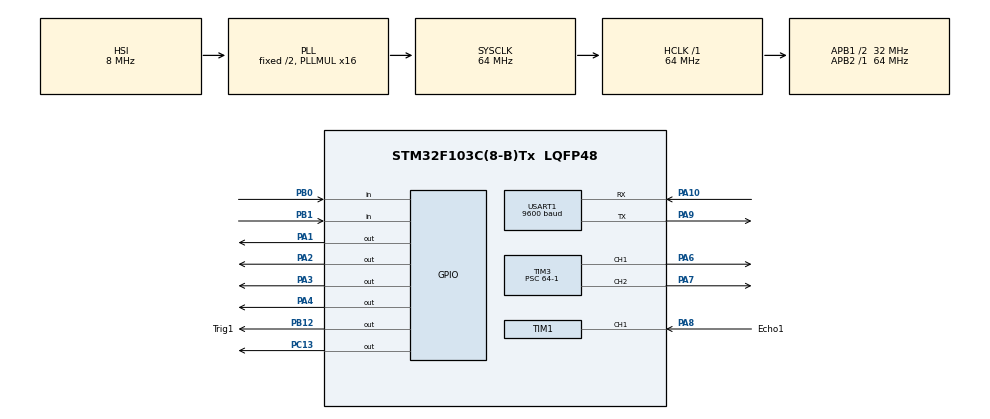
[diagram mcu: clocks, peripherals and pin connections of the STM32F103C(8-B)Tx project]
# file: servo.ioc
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FREERTOS.Tasks01=defaultTask,24,128,StartDefaultTask,Default,NULL,Dynamic,NULL,NULL
Mcu.Family=STM32F1
Mcu.Name=STM32F103C(8-B)Tx
Mcu.Package=LQFP48
NVIC.PriorityGroup=NVIC_PRIORITYGROUP_4
NVIC.TIM1_CC_IRQn=true\:5\:0\:false\:false\:true\:true\:true\:true\:true
NVIC.TIM4_IRQn=true\:15\:0\:false\:false\:true\:false\:false\:true\:true
NVIC.TimeBase=TIM4_IRQn
NVIC.TimeBaseIP=TIM4
NVIC.USART1_IRQn=true\:5\:0\:false\:false\:true\:true\:true\:true\:true
PA1.Signal=GPIO_Output
PA10.Mode=Asynchronous
PA10.Signal=USART1_RX
PA13.Mode=Serial_Wire
PA13.Signal=SYS_JTMS-SWDIO
PA14.Mode=Serial_Wire
PA14.Signal=SYS_JTCK-SWCLK
PA2.Signal=GPIO_Output
PA3.Signal=GPIO_Output
PA4.Signal=GPIO_Output
PA6.Signal=S_TIM3_CH1
PA7.Signal=S_TIM3_CH2
PA8.GPIO_Label=Echo1
PA8.Signal=S_TIM1_CH1
PA9.Mode=Asynchronous
PA9.Signal=USART1_TX
PB0.Signal=GPIO_Input
PB1.Signal=GPIO_Input
PB12.GPIO_Label=Trig1
PB12.Signal=GPIO_Output
PC13-TAMPER-RTC.Signal=GPIO_Output
ProjectManager.HeapSize=0x200
ProjectManager.StackSize=0x400
ProjectManager.TargetToolchain=STM32CubeIDE
RCC.AHBFreq_Value=64000000
RCC.APB1CLKDivider=RCC_HCLK_DIV2
RCC.APB1Freq_Value=32000000
RCC.APB1TimFreq_Value=64000000
RCC.APB2Freq_Value=64000000
RCC.APB2TimFreq_Value=64000000
RCC.HCLKFreq_Value=64000000
RCC.PLLMUL=RCC_PLL_MUL16
RCC.SYSCLKFreq_VALUE=64000000
RCC.SYSCLKSource=RCC_SYSCLKSOURCE_PLLCLK
RCC.USBFreq_Value=64000000
SH.S_TIM1_CH1.0=TIM1_CH1,Input_Capture1_from_TI1
SH.S_TIM3_CH1.0=TIM3_CH1,PWM Generation1 CH1
SH.S_TIM3_CH2.0=TIM3_CH2,PWM Generation2 CH2
TIM1.Channel-Input_Capture1_from_TI1=TIM_CHANNEL_1
TIM1.Prescaler=64-1
TIM2.Prescaler=64-1
TIM3.Channel-PWM\ Generation1\ CH1=TIM_CHANNEL_1
TIM3.Channel-PWM\ Generation2\ CH2=TIM_CHANNEL_2
TIM3.Period=625
TIM3.Prescaler=64-1
USART1.BaudRate=9600
USART1.VirtualMode=VM_ASYNC
VP_FREERTOS_VS_CMSIS_V2.Mode=CMSIS_V2
VP_SYS_VS_tim4.Mode=TIM4
VP_TIM2_VS_ClockSourceINT.Mode=Internal
VP_TIM3_VS_ClockSourceINT.Mode=Internal
board=custom

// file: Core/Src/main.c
/* USER CODE BEGIN Header */
/**
  ******************************************************************************
  * @file           : main.c
  * @brief          : Main program body
  ******************************************************************************
  * @attention
  *
  * Copyright (c) 2024 STMicroelectronics.
  * All rights reserved.
  *
  * This software is licensed under terms that can be found in the LICENSE file
  * in the root directory of this software component.
  * If no LICENSE file comes with this software, it is provided AS-IS.
  *
  ******************************************************************************
  */
/* USER CODE END Header */
#include "main.h"
#include "cmsis_os.h"
#include "tim.h"
#include "usart.h"
#include "gpio.h"

/* USER CODE BEGIN Includes */
#include "task.h"
#include "drive.h"
#include "ACC.h"
#include "ultrasonic.h"
/* USER CODE END Includes */

/* USER CODE BEGIN PV */
TaskHandle_t Distance1_Measure = NULL;
TaskHandle_t Distance2_Measure = NULL;
/* USER CODE END PV */

void SystemClock_Config(void);
void MX_FREERTOS_Init(void);

int main(void)
{

  /* MCU Configuration--------------------------------------------------------*/

  /* Reset of all peripherals, Initializes the Flash interface and the Systick. */
  HAL_Init();

  /* USER CODE BEGIN Init */
  xTaskCreate(drive_task, "Driving Task", 128, ( void * ) 1, 5, NULL);
//  xTaskCreate(get_data_task, "Bluetooth Task", 128, ( void * ) 1, 6, NULL);
//  xTaskCreate(HCSR04_1_Read_task, "HCSR04_1 Task", 100, ( void * ) 1, 1, NULL);
//  xTaskCreate(HCSR04_2_Read_task, "HCSR04_2 Task", 100, ( void * ) 1, 4, NULL);
//  xTaskCreate(blind_spot_task, "blind spot Task", 100, ( void * ) 1, 5, NULL);
   // xTaskCreate(CruiseControl_Task, "CruiseControl", 128, ( void * ) 1, 5, NULL);
    xTaskCreate(Distance1Measure_Task, "Distance 1 Measure", 128, ( void * ) 1, 6, &Distance1_Measure);
//  xTaskCreate(Distance2Measure_Task, "Distance 2 Measure", 128, ( void * ) 1, 6, &Distance2_Measure);
  /* USER CODE END Init */

  /* Configure the system clock */
  SystemClock_Config();

  /* Initialize all configured peripherals */
  MX_GPIO_Init();
  MX_USART1_UART_Init();
  MX_TIM3_Init();
  MX_TIM1_Init();
  MX_TIM2_Init();
  /* USER CODE BEGIN 2 */
//  TIM2->CCR2 = 1500;
//  HAL_TIM_PWM_Start(&htim2, TIM_CHANNEL_2);

  /* USER CODE END 2 */

  /* Init scheduler */
  osKernelInitialize();

  /* Call init function for freertos objects (in cmsis_os2.c) */
  MX_FREERTOS_Init();

  /* Start scheduler */
  osKernelStart();

  /* We should never get here as control is now taken by the scheduler */

  /* Infinite loop */
  while (1)
  {

    /* USER CODE BEGIN 3 */
	  TIM2->CCR2 = 5000;
	  for(int i=0; i<30000; i++);
	  TIM2->CCR2 = 10000;
	  for(int i=0; i<30000; i++);
  }
  /* USER CODE END 3 */
}

void SystemClock_Config(void)
{
  RCC_OscInitTypeDef RCC_OscInitStruct = {0};
  RCC_ClkInitTypeDef RCC_ClkInitStruct = {0};

  /** Initializes the RCC Oscillators according to the specified parameters
  * in the RCC_OscInitTypeDef structure.
  */
  RCC_OscInitStruct.OscillatorType = RCC_OSCILLATORTYPE_HSI;
  RCC_OscInitStruct.HSIState = RCC_HSI_ON;
  RCC_OscInitStruct.HSICalibrationValue = RCC_HSICALIBRATION_DEFAULT;
  RCC_OscInitStruct.PLL.PLLState = RCC_PLL_ON;
  RCC_OscInitStruct.PLL.PLLSource = RCC_PLLSOURCE_HSI_DIV2;
  RCC_OscInitStruct.PLL.PLLMUL = RCC_PLL_MUL16;
  if (HAL_RCC_OscConfig(&RCC_OscInitStruct) != HAL_OK)
  {
    Error_Handler();
  }

  /** Initializes the CPU, AHB and APB buses clocks
  */
  RCC_ClkInitStruct.ClockType = RCC_CLOCKTYPE_HCLK|RCC_CLOCKTYPE_SYSCLK
                              |RCC_CLOCKTYPE_PCLK1|RCC_CLOCKTYPE_PCLK2;
  RCC_ClkInitStruct.SYSCLKSource = RCC_SYSCLKSOURCE_PLLCLK;
  RCC_ClkInitStruct.AHBCLKDivider = RCC_SYSCLK_DIV1;
  RCC_ClkInitStruct.APB1CLKDivider = RCC_HCLK_DIV2;
  RCC_ClkInitStruct.APB2CLKDivider = RCC_HCLK_DIV1;

  if (HAL_RCC_ClockConfig(&RCC_ClkInitStruct, FLASH_LATENCY_2) != HAL_OK)
  {
    Error_Handler();
  }
}

void HAL_TIM_PeriodElapsedCallback(TIM_HandleTypeDef *htim)
{
  if (htim->Instance == TIM4) {
    HAL_IncTick();
  }
}

void Error_Handler(void)
{
  __disable_irq();
  while (1)
  {
  }
}
